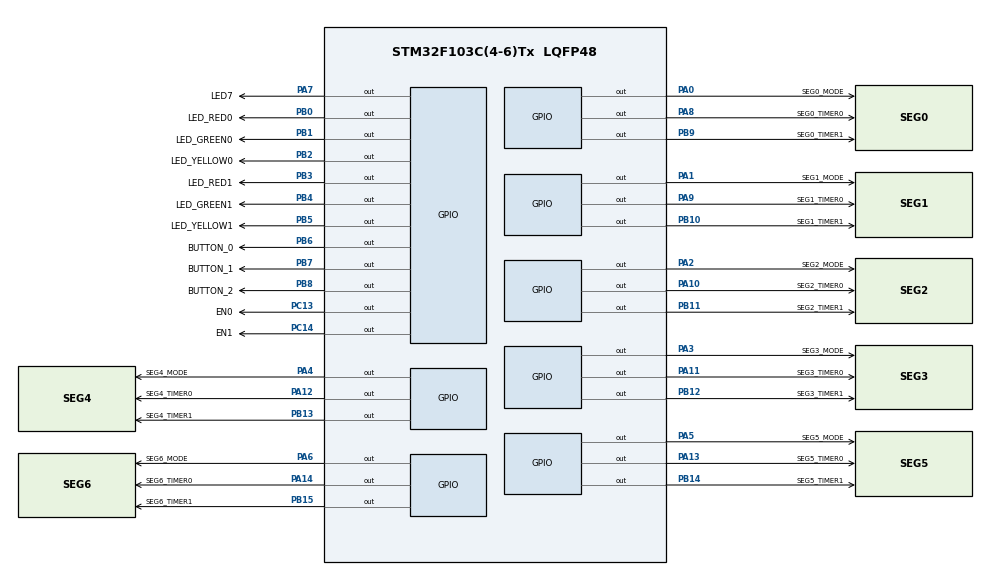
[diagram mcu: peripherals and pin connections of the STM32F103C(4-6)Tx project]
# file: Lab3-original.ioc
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Mcu.Family=STM32F1
Mcu.Name=STM32F103C(4-6)Tx
Mcu.Package=LQFP48
NVIC.PriorityGroup=NVIC_PRIORITYGROUP_4
NVIC.TIM2_IRQn=true\:0\:0\:false\:false\:true\:true\:true\:true
PA0-WKUP.GPIO_Label=SEG0_MODE
PA0-WKUP.Signal=GPIO_Output
PA1.GPIO_Label=SEG1_MODE
PA1.Signal=GPIO_Output
PA10.GPIO_Label=SEG2_TIMER0
PA10.Signal=GPIO_Output
PA11.GPIO_Label=SEG3_TIMER0
PA11.Signal=GPIO_Output
PA12.GPIO_Label=SEG4_TIMER0
PA12.Signal=GPIO_Output
PA13.GPIO_Label=SEG5_TIMER0
PA13.Signal=GPIO_Output
PA14.GPIO_Label=SEG6_TIMER0
PA14.Signal=GPIO_Output
PA2.GPIO_Label=SEG2_MODE
PA2.Signal=GPIO_Output
PA3.GPIO_Label=SEG3_MODE
PA3.Signal=GPIO_Output
PA4.GPIO_Label=SEG4_MODE
PA4.Signal=GPIO_Output
PA5.GPIO_Label=SEG5_MODE
PA5.Signal=GPIO_Output
PA6.GPIO_Label=SEG6_MODE
PA6.Signal=GPIO_Output
PA7.GPIO_Label=LED7
PA7.Signal=GPIO_Output
PA8.GPIO_Label=SEG0_TIMER0
PA8.Signal=GPIO_Output
PA9.GPIO_Label=SEG1_TIMER0
PA9.Signal=GPIO_Output
PB0.GPIO_Label=LED_RED0
PB0.Signal=GPIO_Output
PB1.GPIO_Label=LED_GREEN0
PB1.Signal=GPIO_Output
PB10.GPIO_Label=SEG1_TIMER1
PB10.Signal=GPIO_Output
PB11.GPIO_Label=SEG2_TIMER1
PB11.Signal=GPIO_Output
PB12.GPIO_Label=SEG3_TIMER1
PB12.Signal=GPIO_Output
PB13.GPIO_Label=SEG4_TIMER1
PB13.Signal=GPIO_Output
PB14.GPIO_Label=SEG5_TIMER1
PB14.Signal=GPIO_Output
PB15.GPIO_Label=SEG6_TIMER1
PB15.Signal=GPIO_Output
PB2.GPIO_Label=LED_YELLOW0
PB2.Signal=GPIO_Output
PB3.GPIO_Label=LED_RED1
PB3.Signal=GPIO_Output
PB4.GPIO_Label=LED_GREEN1
PB4.Signal=GPIO_Output
PB5.GPIO_Label=LED_YELLOW1
PB5.Signal=GPIO_Output
PB6.GPIO_Label=BUTTON_0
PB6.GPIO_PuPd=GPIO_PULLUP
PB6.Signal=GPIO_Output
PB7.GPIO_Label=BUTTON_1
PB7.GPIO_PuPd=GPIO_PULLUP
PB7.Signal=GPIO_Output
PB8.GPIO_Label=BUTTON_2
PB8.GPIO_PuPd=GPIO_PULLUP
PB8.Signal=GPIO_Output
PB9.GPIO_Label=SEG0_TIMER1
PB9.Signal=GPIO_Output
PC13-TAMPER-RTC.GPIO_Label=EN0
PC13-TAMPER-RTC.Signal=GPIO_Output
PC14-OSC32_IN.GPIO_Label=EN1
PC14-OSC32_IN.Signal=GPIO_Output
ProjectManager.HeapSize=0x200
ProjectManager.StackSize=0x400
ProjectManager.TargetToolchain=STM32CubeIDE
RCC.APB1Freq_Value=8000000
RCC.APB2Freq_Value=8000000
TIM2.Period=9
TIM2.Prescaler=7999
VP_SYS_VS_ND.Mode=No_Debug
VP_TIM2_VS_ClockSourceINT.Mode=Internal
board=custom

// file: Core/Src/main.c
/* USER CODE BEGIN Header */
/**
  ******************************************************************************
  * @file           : main.c
  * @brief          : Main program body
  ******************************************************************************
  * @attention
  *
  * Copyright (c) 2025 STMicroelectronics.
  * All rights reserved.
  *
  * This software is licensed under terms that can be found in the LICENSE file
  * in the root directory of this software component.
  * If no LICENSE file comes with this software, it is provided AS-IS.
  *
  ******************************************************************************
  */
/* USER CODE END Header */
#include "main.h"

/* USER CODE BEGIN Includes */
#include "input_reading.h"
#include "input_processing.h"
#include "fsm_traffic.h"
#include "led_display.h"
#include "timer.h"

/* USER CODE END Includes */

TIM_HandleTypeDef htim2;

static uint32_t pre;
static uint32_t per;

void SystemClock_Config(void);
static void MX_GPIO_Init(void);
static void MX_TIM2_Init(void);
uint32_t TIMER_PERIOD_MS;

int main(void)
{

  /* MCU Configuration--------------------------------------------------------*/

  /* Reset of all peripherals, Initializes the Flash interface and the Systick. */
  HAL_Init();

  /* Configure the system clock */
  SystemClock_Config();

  /* Initialize all configured peripherals */
  MX_GPIO_Init();
  MX_TIM2_Init();
  pre = htim2.Init.Prescaler + 1;
  per = htim2.Init.Period + 1;
  uint32_t system_clock = 8000000UL;  // Hz, từ HSI (hoặc dùng HAL_RCC_GetHCLKFreq() nếu clock động)

  uint32_t timer_freq = system_clock / (pre + 1);
  TIMER_PERIOD_MS = (1000UL * (per + 1)) / timer_freq;
  // TIMER_PERIOD_MS = 10;

  /* USER CODE BEGIN 2 */
  HAL_TIM_Base_Start_IT(&htim2);

  /* USER CODE END 2 */

  /* Infinite loop */
  while (1)
  {

    /* USER CODE BEGIN 3 */
	  if (timer4_flag == 1)
	  {
		fsm_for_input_processing();
		displayMode();

		fsm_traffic();
		timer_line0 = timer2;
		timer_line1 = timer3;
		displayTimer();
		setTimer4(100);
	  }

  }
  /* USER CODE END 3 */
}

void SystemClock_Config(void)
{
  RCC_OscInitTypeDef RCC_OscInitStruct = {0};
  RCC_ClkInitTypeDef RCC_ClkInitStruct = {0};

  /** Initializes the RCC Oscillators according to the specified parameters
  * in the RCC_OscInitTypeDef structure.
  */
  RCC_OscInitStruct.OscillatorType = RCC_OSCILLATORTYPE_HSI;
  RCC_OscInitStruct.HSIState = RCC_HSI_ON;
  RCC_OscInitStruct.HSICalibrationValue = RCC_HSICALIBRATION_DEFAULT;
  RCC_OscInitStruct.PLL.PLLState = RCC_PLL_NONE;
  if (HAL_RCC_OscConfig(&RCC_OscInitStruct) != HAL_OK)
  {
    Error_Handler();
  }

  /** Initializes the CPU, AHB and APB buses clocks
  */
  RCC_ClkInitStruct.ClockType = RCC_CLOCKTYPE_HCLK|RCC_CLOCKTYPE_SYSCLK
                              |RCC_CLOCKTYPE_PCLK1|RCC_CLOCKTYPE_PCLK2;
  RCC_ClkInitStruct.SYSCLKSource = RCC_SYSCLKSOURCE_HSI;
  RCC_ClkInitStruct.AHBCLKDivider = RCC_SYSCLK_DIV1;
  RCC_ClkInitStruct.APB1CLKDivider = RCC_HCLK_DIV1;
  RCC_ClkInitStruct.APB2CLKDivider = RCC_HCLK_DIV1;

  if (HAL_RCC_ClockConfig(&RCC_ClkInitStruct, FLASH_LATENCY_0) != HAL_OK)
  {
    Error_Handler();
  }
}

static void MX_TIM2_Init(void)
{

  TIM_ClockConfigTypeDef sClockSourceConfig = {0};
  TIM_MasterConfigTypeDef sMasterConfig = {0};

  htim2.Instance = TIM2;
  htim2.Init.Prescaler = 7999;
  htim2.Init.CounterMode = TIM_COUNTERMODE_UP;
  htim2.Init.Period = 9;
  htim2.Init.ClockDivision = TIM_CLOCKDIVISION_DIV1;
  htim2.Init.AutoReloadPreload = TIM_AUTORELOAD_PRELOAD_DISABLE;
  if (HAL_TIM_Base_Init(&htim2) != HAL_OK)
  {
    Error_Handler();
  }
  sClockSourceConfig.ClockSource = TIM_CLOCKSOURCE_INTERNAL;
  if (HAL_TIM_ConfigClockSource(&htim2, &sClockSourceConfig) != HAL_OK)
  {
    Error_Handler();
  }
  sMasterConfig.MasterOutputTrigger = TIM_TRGO_RESET;
  sMasterConfig.MasterSlaveMode = TIM_MASTERSLAVEMODE_DISABLE;
  if (HAL_TIMEx_MasterConfigSynchronization(&htim2, &sMasterConfig) != HAL_OK)
  {
    Error_Handler();
  }

}

static void MX_GPIO_Init(void)
{
  GPIO_InitTypeDef GPIO_InitStruct = {0};

  /* GPIO Ports Clock Enable */
  __HAL_RCC_GPIOC_CLK_ENABLE();
  __HAL_RCC_GPIOA_CLK_ENABLE();
  __HAL_RCC_GPIOB_CLK_ENABLE();

  /*Configure GPIO pin Output Level */
  HAL_GPIO_WritePin(GPIOC, EN0_Pin|EN1_Pin, GPIO_PIN_SET);

  /*Configure GPIO pin Output Level */
  HAL_GPIO_WritePin(GPIOA, SEG0_MODE_Pin|SEG1_MODE_Pin|SEG2_MODE_Pin|SEG3_MODE_Pin
                          |SEG4_MODE_Pin|SEG5_MODE_Pin|SEG6_MODE_Pin|LED7_Pin
                          |SEG0_TIMER0_Pin|SEG1_TIMER0_Pin|SEG2_TIMER0_Pin|SEG3_TIMER0_Pin
                          |SEG4_TIMER0_Pin|SEG5_TIMER0_Pin|SEG6_TIMER0_Pin, GPIO_PIN_SET);

  /*Configure GPIO pin Output Level */
  HAL_GPIO_WritePin(GPIOB, LED_RED0_Pin|LED_GREEN0_Pin|LED_YELLOW0_Pin|SEG1_TIMER1_Pin
                          |SEG2_TIMER1_Pin|SEG3_TIMER1_Pin|SEG4_TIMER1_Pin|SEG5_TIMER1_Pin
                          |SEG6_TIMER1_Pin|LED_RED1_Pin|LED_GREEN1_Pin|LED_YELLOW1_Pin
                          |BUTTON_0_Pin|BUTTON_1_Pin|BUTTON_2_Pin|SEG0_TIMER1_Pin, GPIO_PIN_SET);

  /*Configure GPIO pins : EN0_Pin EN1_Pin */
  GPIO_InitStruct.Pin = EN0_Pin|EN1_Pin;
  GPIO_InitStruct.Mode = GPIO_MODE_OUTPUT_PP;
  GPIO_InitStruct.Pull = GPIO_NOPULL;
  GPIO_InitStruct.Speed = GPIO_SPEED_FREQ_LOW;
  HAL_GPIO_Init(GPIOC, &GPIO_InitStruct);

  /*Configure GPIO pins : SEG0_MODE_Pin SEG1_MODE_Pin SEG2_MODE_Pin SEG3_MODE_Pin
                           SEG4_MODE_Pin SEG5_MODE_Pin SEG6_MODE_Pin LED7_Pin
                           SEG0_TIMER0_Pin SEG1_TIMER0_Pin SEG2_TIMER0_Pin SEG3_TIMER0_Pin
                           SEG4_TIMER0_Pin SEG5_TIMER0_Pin SEG6_TIMER0_Pin */
  GPIO_InitStruct.Pin = SEG0_MODE_Pin|SEG1_MODE_Pin|SEG2_MODE_Pin|SEG3_MODE_Pin
                          |SEG4_MODE_Pin|SEG5_MODE_Pin|SEG6_MODE_Pin|LED7_Pin
                          |SEG0_TIMER0_Pin|SEG1_TIMER0_Pin|SEG2_TIMER0_Pin|SEG3_TIMER0_Pin
                          |SEG4_TIMER0_Pin|SEG5_TIMER0_Pin|SEG6_TIMER0_Pin;
  GPIO_InitStruct.Mode = GPIO_MODE_OUTPUT_PP;
  GPIO_InitStruct.Pull = GPIO_NOPULL;
  GPIO_InitStruct.Speed = GPIO_SPEED_FREQ_LOW;
  HAL_GPIO_Init(GPIOA, &GPIO_InitStruct);

  /*Configure GPIO pins : LED_RED0_Pin LED_GREEN0_Pin LED_YELLOW0_Pin SEG1_TIMER1_Pin
                           SEG2_TIMER1_Pin SEG3_TIMER1_Pin SEG4_TIMER1_Pin SEG5_TIMER1_Pin
                           SEG6_TIMER1_Pin LED_RED1_Pin LED_GREEN1_Pin LED_YELLOW1_Pin
                           SEG0_TIMER1_Pin */
  GPIO_InitStruct.Pin = LED_RED0_Pin|LED_GREEN0_Pin|LED_YELLOW0_Pin|SEG1_TIMER1_Pin
                          |SEG2_TIMER1_Pin|SEG3_TIMER1_Pin|SEG4_TIMER1_Pin|SEG5_TIMER1_Pin
                          |SEG6_TIMER1_Pin|LED_RED1_Pin|LED_GREEN1_Pin|LED_YELLOW1_Pin
                          |SEG0_TIMER1_Pin;
  GPIO_InitStruct.Mode = GPIO_MODE_OUTPUT_PP;
  GPIO_InitStruct.Pull = GPIO_NOPULL;
  GPIO_InitStruct.Speed = GPIO_SPEED_FREQ_LOW;
  HAL_GPIO_Init(GPIOB, &GPIO_InitStruct);

  /*Configure GPIO pins : BUTTON_0_Pin BUTTON_1_Pin BUTTON_2_Pin */
  GPIO_InitStruct.Pin = BUTTON_0_Pin|BUTTON_1_Pin|BUTTON_2_Pin;
  GPIO_InitStruct.Mode = GPIO_MODE_OUTPUT_PP;
  GPIO_InitStruct.Pull = GPIO_PULLUP;
  GPIO_InitStruct.Speed = GPIO_SPEED_FREQ_LOW;
  HAL_GPIO_Init(GPIOB, &GPIO_InitStruct);

}

void Error_Handler(void)
{
  __disable_irq();
  while (1)
  {
  }
}
